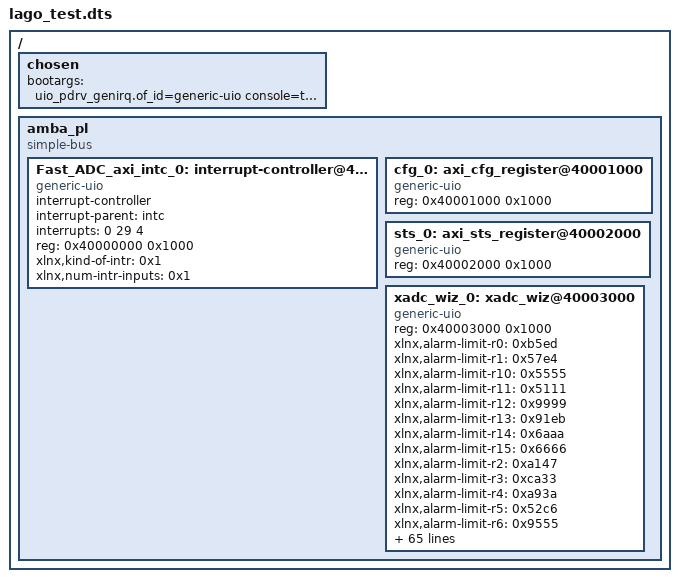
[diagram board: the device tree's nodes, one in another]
/include/ "system.dts"

/ {
	chosen {
		bootargs = "uio_pdrv_genirq.of_id=generic-uio console=ttyPS0,115200 root=/dev/mmcblk0p2 ro rootfstype=ext4 earlyprintk rootwait";
	};

  amba_pl: amba_pl {
    #address-cells = <1>;
    #size-cells = <1>;
    compatible = "simple-bus";
    ranges ;
    Fast_ADC_axi_intc_0: interrupt-controller@40000000 {
      #interrupt-cells = <2>;
      compatible = "generic-uio";
      interrupt-controller ;
      interrupt-parent = <&intc>;
      interrupts = <0 29 4>;
      reg = <0x40000000 0x1000>;
      xlnx,kind-of-intr = <0x1>;
      xlnx,num-intr-inputs = <0x1>;
    };
    cfg_0: axi_cfg_register@40001000 {
      compatible = "generic-uio";
      reg = <0x40001000 0x1000>;
    };
    sts_0: axi_sts_register@40002000 {
      compatible = "generic-uio";
      reg = <0x40002000 0x1000>;
    };
    xadc_wiz_0: xadc_wiz@40003000 {
      compatible = "generic-uio";
      reg = <0x40003000 0x1000>;
      xlnx,alarm-limit-r0 = <0xb5ed>;
      xlnx,alarm-limit-r1 = <0x57e4>;
      xlnx,alarm-limit-r10 = <0x5555>;
      xlnx,alarm-limit-r11 = <0x5111>;
      xlnx,alarm-limit-r12 = <0x9999>;
      xlnx,alarm-limit-r13 = <0x91eb>;
      xlnx,alarm-limit-r14 = <0x6aaa>;
      xlnx,alarm-limit-r15 = <0x6666>;
      xlnx,alarm-limit-r2 = <0xa147>;
      xlnx,alarm-limit-r3 = <0xca33>;
      xlnx,alarm-limit-r4 = <0xa93a>;
      xlnx,alarm-limit-r5 = <0x52c6>;
      xlnx,alarm-limit-r6 = <0x9555>;
      xlnx,alarm-limit-r7 = <0xae4e>;
      xlnx,alarm-limit-r8 = <0x5999>;
      xlnx,alarm-limit-r9 = <0x5111>;
      xlnx,configuration-r0 = <0x0>;
      xlnx,configuration-r1 = <0x21af>;
      xlnx,configuration-r2 = <0x400>;
      xlnx,dclk-frequency = <0x64>;
      xlnx,external-mux-channel = "VP_VN";
      xlnx,external-muxaddr-enable = <0x0>;
      xlnx,fifo-depth = <0x7>;
      xlnx,has-axi = <0x1>;
      xlnx,has-axi4stream = <0x0>;
      xlnx,has-busy = <0x1>;
      xlnx,has-channel = <0x1>;
      xlnx,has-convst = <0x0>;
      xlnx,has-convstclk = <0x0>;
      xlnx,has-dclk = <0x1>;
      xlnx,has-drp = <0x0>;
      xlnx,has-eoc = <0x1>;
      xlnx,has-eos = <0x1>;
      xlnx,has-external-mux = <0x0>;
      xlnx,has-jtagbusy = <0x0>;
      xlnx,has-jtaglocked = <0x0>;
      xlnx,has-jtagmodified = <0x0>;
      xlnx,has-ot-alarm = <0x0>;
      xlnx,has-reset = <0x0>;
      xlnx,has-temp-bus = <0x0>;
      xlnx,has-user-temp-alarm = <0x0>;
      xlnx,has-vbram-alarm = <0x0>;
      xlnx,has-vccaux-alarm = <0x0>;
      xlnx,has-vccddro-alarm = <0x0>;
      xlnx,has-vccint-alarm = <0x0>;
      xlnx,has-vccpaux-alarm = <0x0>;
      xlnx,has-vccpint-alarm = <0x0>;
      xlnx,has-vn = <0x1>;
      xlnx,has-vp = <0x1>;
      xlnx,include-intr = <0x1>;
      xlnx,sampling-rate = "961538.4615384615";
      xlnx,sequence-r0 = <0xb01>;
      xlnx,sequence-r1 = <0x303>;
      xlnx,sequence-r2 = <0xb00>;
      xlnx,sequence-r3 = <0x303>;
      xlnx,sequence-r4 = <0x0>;
      xlnx,sequence-r5 = <0x0>;
      xlnx,sequence-r6 = <0x0>;
      xlnx,sequence-r7 = <0x0>;
      xlnx,sim-file-name = "design";
      xlnx,sim-file-rel-path = "./";
      xlnx,sim-file-sel = "Default";
      xlnx,vaux0 = <0x1>;
      xlnx,vaux1 = <0x1>;
      xlnx,vaux10 = <0x0>;
      xlnx,vaux11 = <0x0>;
      xlnx,vaux12 = <0x0>;
      xlnx,vaux13 = <0x0>;
      xlnx,vaux14 = <0x0>;
      xlnx,vaux15 = <0x0>;
      xlnx,vaux2 = <0x0>;
      xlnx,vaux3 = <0x0>;
      xlnx,vaux4 = <0x0>;
      xlnx,vaux5 = <0x0>;
      xlnx,vaux6 = <0x0>;
      xlnx,vaux7 = <0x0>;
      xlnx,vaux8 = <0x1>;
      xlnx,vaux9 = <0x1>;
    };
  };
};


